# ESP32C5_RADIO register map
Vendor: Espressif; Series: ESP32-C5; File version: 0.1
Registers are 32-bit, read-write, no defined reset value unless marked. A register's access mark holds for its fields unless they carry their own. Offsets are from the block's base; [hi:lo] are bit positions; {n}, {i} and the like mark numbered series; <NAME> marks a mode.

## SYSTIMER_COUNTER — The counter latch of system timer unit zero: the UPDATE strobe copies the counter into VALUE_HI and VALUE_LO and VALUE_VALID reports the copy done. Every context reads the counter, so this is a shared block: a strobe writes UPDATE alone and the values are read without a side effect.
Base 0x6000A004
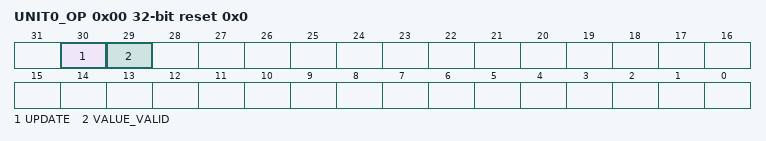
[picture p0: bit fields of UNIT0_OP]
0x00 UNIT0_OP reset 0x0 — Project-assigned name. Unit zero's latch strobe and its done flag.
  [30] UPDATE wo — Project-assigned name. Writing one latches unit zero's count into VALUE_HI and VALUE_LO.
  [29] VALUE_VALID ro — Project-assigned name. Set when the latched value is synchronized and valid (R/SS/WTC: a written one clears it, so the strobe writes zero here).
0x3C UNIT0_VALUE_HI ro reset 0x0 — Project-assigned name. High 20 bits of unit zero's latched count.
  [19:0] VALUE_HI — Project-assigned name. Count bits 51:32.
0x40 UNIT0_VALUE_LO ro reset 0x0 — Project-assigned name. Low 32 bits of unit zero's latched count.
  [31:0] VALUE_LO — Project-assigned name. Count bits 31:0.

## SYSTIMER_ACKNOWLEDGE — The comparators' interrupt acknowledgements. Each comparator's alarm handler strobes its own bit alone, from its own context, so this is a shared block of write-trigger strobes.
Base 0x6000A06C
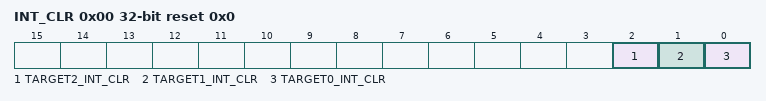
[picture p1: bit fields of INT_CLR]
0x00 INT_CLR wo reset 0x0 write-1-clears — Project-assigned name. Comparator interrupt acknowledgements: a written one clears the raw bit.
  [2] TARGET2_INT_CLR — Project-assigned name. Clears comparator 2's interrupt.
  [1] TARGET1_INT_CLR — Project-assigned name. Clears comparator 1's interrupt.
  [0] TARGET0_INT_CLR — Project-assigned name. Clears comparator 0's interrupt.

## FROM_CPU_0 — Software interrupt line 0 (interrupt source FROM_CPU_INTR0): one level bit a store of one raises and a store of zero lowers. Wakers raise it from every context and the line's handler lowers it, so it is a shared block whose one register is stored whole.
Base 0x600C5090
0x00 LINE reset 0x0 — Project-assigned name. The level of software interrupt line 0.
  [0] RAISED — Project-assigned name. One raises the line's interrupt; zero lowers it.

## FROM_CPU_1 — Software interrupt line 1 (interrupt source FROM_CPU_INTR1): one level bit a store of one raises and a store of zero lowers. Wakers raise it from every context and the line's handler lowers it, so it is a shared block whose one register is stored whole.
Base 0x600C5094
0x00 LINE reset 0x0 — Project-assigned name. The level of software interrupt line 1.
  [0] RAISED — Project-assigned name. One raises the line's interrupt; zero lowers it.

## FROM_CPU_2 — Software interrupt line 2 (interrupt source FROM_CPU_INTR2): one level bit a store of one raises and a store of zero lowers. Wakers raise it from every context and the line's handler lowers it, so it is a shared block whose one register is stored whole.
Base 0x600C5098
0x00 LINE reset 0x0 — Project-assigned name. The level of software interrupt line 2.
  [0] RAISED — Project-assigned name. One raises the line's interrupt; zero lowers it.

## FROM_CPU_3 — Software interrupt line 3 (interrupt source FROM_CPU_INTR3): one level bit a store of one raises and a store of zero lowers. Wakers raise it from every context and the line's handler lowers it, so it is a shared block whose one register is stored whole.
Base 0x600C509C
0x00 LINE reset 0x0 — Project-assigned name. The level of software interrupt line 3.
  [0] RAISED — Project-assigned name. One raises the line's interrupt; zero lowers it.

## CLIC — The core-local interrupt controller of the hart that accesses it, as 32-bit words: each line's word holds its pending, enable, attribute and control bytes. Invariant: every vectored line is level-triggered, so a write of the word that changes its enable or control writes back the pending bit read without losing or inventing an interrupt (SOURCE: ESP_HAL_1F646C5_CLIC_LEVEL_LINES). INT_CONFIG holds the number of level bits of each line's control byte.
Base 0x20800000
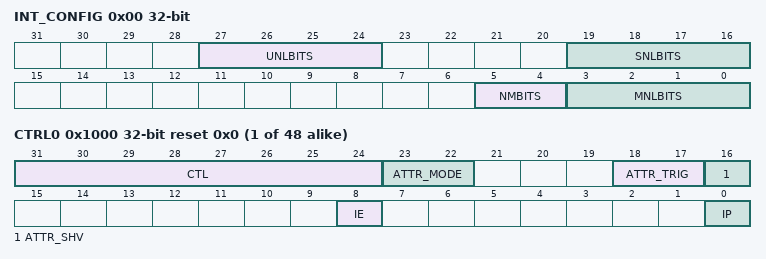
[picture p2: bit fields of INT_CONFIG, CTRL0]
0x00 INT_CONFIG — Project-assigned name. The controller's configuration: how many bits of a line's control byte are its level.
  [27:24] UNLBITS — Project-assigned name. User mode: the number of level bits of a line's control byte, at most 8.
  [19:16] SNLBITS — Project-assigned name. Supervisor mode: the number of level bits of a line's control byte, at most 8.
  [5:4] NMBITS — Project-assigned name. The number of privilege-mode bits of a line's attribute.
  [3:0] MNLBITS — Project-assigned name. Machine mode: the number of high bits of a line's control byte that are its level, at most 8.
{0x1000+4i} CTRL{i} (i=0..47) reset 0x0 — Project-assigned name. Line {i}: pending, enable, attribute and level control.
  [31:24] CTL — Project-assigned name. Level and priority control; with three level bits a level-n line holds 0x1f | (n - 1) << 5.
  [23:22] ATTR_MODE — Project-assigned name. Privilege mode of the line.
  [18:17] ATTR_TRIG — Project-assigned name. Trigger: bit 0 clear is level, set is edge; bit 1 selects the negative polarity.
  [16] ATTR_SHV — Project-assigned name. Selects hardware vectoring for the line.
  [8] IE — Project-assigned name. Enables the line.
  [0] IP — Project-assigned name. The line's pending bit; for a level-triggered line it follows the source.

## INTERRUPT_CORE0 — The interrupt-matrix route words of core 0, one per peripheral source, by source number, ZB_MAC (source 12) included.
Base 0x60010000
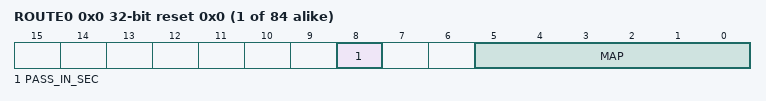
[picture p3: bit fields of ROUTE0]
{0x0+4i} ROUTE{i} (i=0..83) reset 0x0 — Project-assigned name. Route of source {i}.
  [8] PASS_IN_SEC — Project-assigned name. The PASS_IN_SEC flag of the source.
  [5:0] MAP — Project-assigned name. The CPU interrupt line the source is routed to; zero routes it nowhere.

## INTERRUPT_CORE0_STATUS — The pending state of every peripheral source at core 0's interrupt matrix. Every context polls it, so it is a shared block of side-effect-free reads.
Base 0x60010150
0x00 INT_STATUS_0 ro reset 0x0 — Project-assigned name. Pending state of sources 0 to 31, one bit each.
  [31:0] SOURCES — Project-assigned name. Bit k is set while source 0 + k raises its interrupt.
0x04 INT_STATUS_1 ro reset 0x0 — Project-assigned name. Pending state of sources 32 to 63, one bit each.
  [31:0] SOURCES — Project-assigned name. Bit k is set while source 32 + k raises its interrupt.
0x08 INT_STATUS_2 ro reset 0x0 — Project-assigned name. Pending state of sources 64 to 83, one bit each.
  [19:0] SOURCES — Project-assigned name. Bit k is set while source 64 + k raises its interrupt.

## WIFI_MAC_INTERFACE_ADDRESS — Four interface-address pairs consumed by MAC receive filtering.
Base 0x600A405C
{0x0+8i} ADDRESS_LOW{i} (i=0..3) — Project-assigned name. Interface MAC bytes 0..3 in little-endian order, published by the first full-word store.
  [31:0] BYTES_0_3 — Project-assigned name.
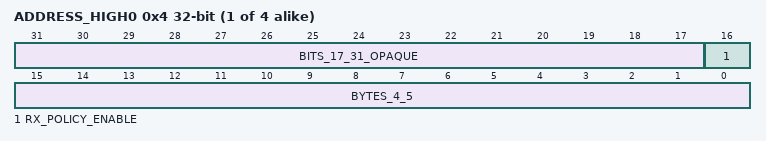
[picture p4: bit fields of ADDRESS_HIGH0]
{0x4+8i} ADDRESS_HIGH{i} (i=0..3) — Project-assigned name. Interface MAC bytes 4..5 are published as a full-word store before a separate fresh-read RMW sets receive-policy enable bit 16.
  [31:17] BITS_17_31_OPAQUE — Opaque: meaning not established.
  [16] RX_POLICY_ENABLE — Project-assigned name. Set by a separate fresh-read RMW in hal_mac_set_addr and by the reachable associated-STA policy branch.
  [15:0] BYTES_4_5 — Project-assigned name.
